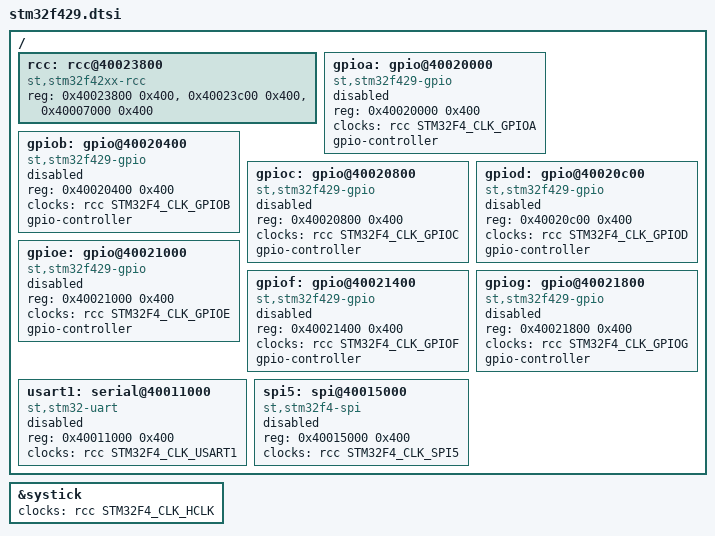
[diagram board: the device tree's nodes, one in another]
/*
 * The blocks of the STM32F429 that mini-boot has drivers for (RM0090).
 * Every board on this SoC includes this file. Peripherals are disabled
 * here; a board enables the ones it uses (&usart1 { status = "okay"; }).
 * The RCC and SysTick are always used.
 *
 * Addresses are written as numbers, as in every Linux .dts: the unit
 * address in a node's name must match its reg.
 */

#include <dt-bindings/clock/stm32f4-rcc.h>
#include "armv7-m.dtsi"

/ {
	#address-cells = <1>;
	#size-cells = <1>;

	/* RCC, and the two blocks whose fields follow the clock */
	rcc: rcc@40023800 {
		compatible = "st,stm32f42xx-rcc";
		reg = <0x40023800 0x400>, <0x40023c00 0x400>, <0x40007000 0x400>;
		reg-names = "rcc", "flash", "pwr";
		#clock-cells = <1>;
	};

	gpioa: gpio@40020000 {
		compatible = "st,stm32f429-gpio";
		reg = <0x40020000 0x400>;
		clocks = <&rcc STM32F4_CLK_GPIOA>;
		gpio-controller;
		#gpio-cells = <2>;
		status = "disabled";
	};

	gpiob: gpio@40020400 {
		compatible = "st,stm32f429-gpio";
		reg = <0x40020400 0x400>;
		clocks = <&rcc STM32F4_CLK_GPIOB>;
		gpio-controller;
		#gpio-cells = <2>;
		status = "disabled";
	};

	gpioc: gpio@40020800 {
		compatible = "st,stm32f429-gpio";
		reg = <0x40020800 0x400>;
		clocks = <&rcc STM32F4_CLK_GPIOC>;
		gpio-controller;
		#gpio-cells = <2>;
		status = "disabled";
	};

	gpiod: gpio@40020c00 {
		compatible = "st,stm32f429-gpio";
		reg = <0x40020c00 0x400>;
		clocks = <&rcc STM32F4_CLK_GPIOD>;
		gpio-controller;
		#gpio-cells = <2>;
		status = "disabled";
	};

	gpioe: gpio@40021000 {
		compatible = "st,stm32f429-gpio";
		reg = <0x40021000 0x400>;
		clocks = <&rcc STM32F4_CLK_GPIOE>;
		gpio-controller;
		#gpio-cells = <2>;
		status = "disabled";
	};

	gpiof: gpio@40021400 {
		compatible = "st,stm32f429-gpio";
		reg = <0x40021400 0x400>;
		clocks = <&rcc STM32F4_CLK_GPIOF>;
		gpio-controller;
		#gpio-cells = <2>;
		status = "disabled";
	};

	gpiog: gpio@40021800 {
		compatible = "st,stm32f429-gpio";
		reg = <0x40021800 0x400>;
		clocks = <&rcc STM32F4_CLK_GPIOG>;
		gpio-controller;
		#gpio-cells = <2>;
		status = "disabled";
	};

	usart1: serial@40011000 {
		compatible = "st,stm32-uart";
		reg = <0x40011000 0x400>;
		clocks = <&rcc STM32F4_CLK_USART1>;
		status = "disabled";
	};

	spi5: spi@40015000 {
		compatible = "st,stm32f4-spi";
		reg = <0x40015000 0x400>;
		clocks = <&rcc STM32F4_CLK_SPI5>;
		#address-cells = <1>;
		#size-cells = <0>;
		status = "disabled";
	};
};

/* SysTick runs on the CPU clock on this SoC */
&systick {
	clocks = <&rcc STM32F4_CLK_HCLK>;
};
